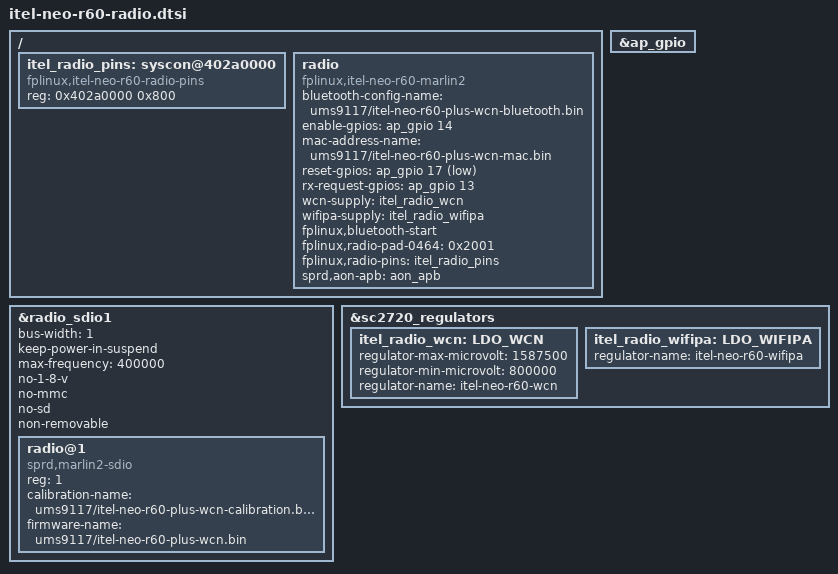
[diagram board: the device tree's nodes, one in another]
// SPDX-License-Identifier: GPL-2.0-only

#include <dt-bindings/gpio/gpio.h>
#include "ums9117-marlin2-sdio.dtsi"

/ {
	itel_radio_pins: syscon@402a0000 {
		compatible = "fplinux,itel-neo-r60-radio-pins", "syscon";
		reg = <0x402a0000 0x800>;
	};

	radio {
		compatible = "fplinux,itel-neo-r60-marlin2";
		bluetooth-config-name = "ums9117/itel-neo-r60-plus-wcn-bluetooth.bin";
		enable-gpios = <&ap_gpio 14 GPIO_ACTIVE_HIGH>;
		mac-address-name = "ums9117/itel-neo-r60-plus-wcn-mac.bin";
		reset-gpios = <&ap_gpio 17 GPIO_ACTIVE_LOW>;
		rx-request-gpios = <&ap_gpio 13 GPIO_ACTIVE_HIGH>;
		wcn-supply = <&itel_radio_wcn>;
		wifipa-supply = <&itel_radio_wifipa>;
		fplinux,bluetooth-start;
		fplinux,radio-pad-0464 = <0x2001>;
		fplinux,radio-pins = <&itel_radio_pins>;
		sprd,aon-apb = <&aon_apb>;
	};
};

&radio_sdio1 {
	bus-width = <1>;
	keep-power-in-suspend;
	max-frequency = <400000>;
	no-1-8-v;
	no-mmc;
	no-sd;
	non-removable;

	radio@1 {
		compatible = "sprd,marlin2-sdio";
		reg = <1>;
		calibration-name = "ums9117/itel-neo-r60-plus-wcn-calibration.bin";
		firmware-name = "ums9117/itel-neo-r60-plus-wcn.bin";
	};
};

&ap_gpio {
	status = "okay";
};

&sc2720_regulators {
	itel_radio_wcn: LDO_WCN {
		regulator-max-microvolt = <1587500>;
		regulator-min-microvolt = <800000>;
		regulator-name = "itel-neo-r60-wcn";
	};

	itel_radio_wifipa: LDO_WIFIPA {
		regulator-name = "itel-neo-r60-wifipa";
	};
};
